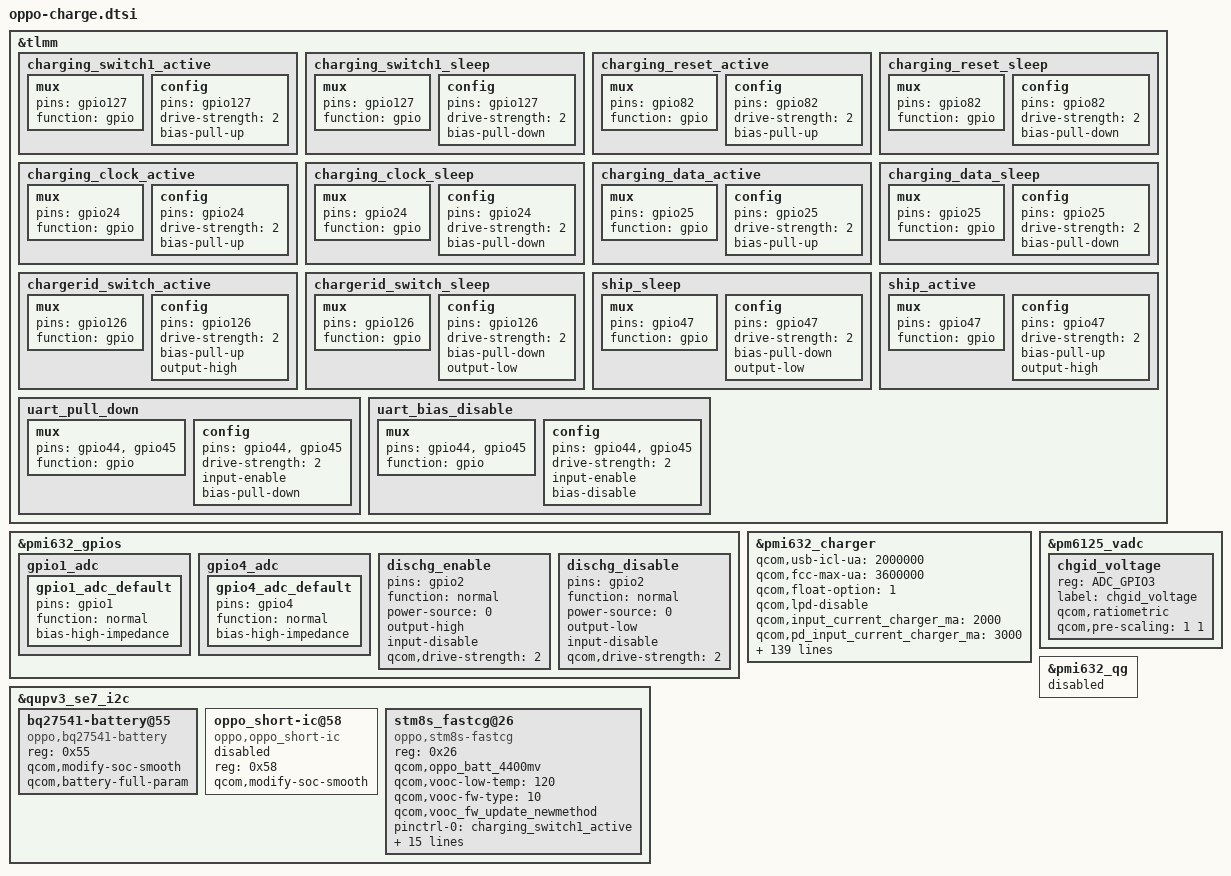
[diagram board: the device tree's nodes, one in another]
/**********************************************************************************
* Copyright (c)  2008-2019  Guangdong OPPO Mobile Comm Corp., Ltd
* VENDOR_EDIT
* Description: OPPO Charge Module Device Tree
*
* Version: 1.0
* Date: 2019-06-10
* Author: Yichun.Chen
*
* ------------------------------ Revision History: --------------------------------
* <version>           <date>                <author>                            <desc>
* Revision 1.0       2019-06-10            Yichun.Chen             Created for new architecture
***********************************************************************************/

&tlmm {
	charging_switch1_active: charging_switch1_active {
		mux {
			pins = "gpio127";
			function = "gpio";
		};

		config {
			pins = "gpio127";
			drive-strength = <2>;
			bias-pull-up;
		};
	};

	charging_switch1_sleep: charging_switch1_sleep {
		mux {
			pins = "gpio127";
			function = "gpio";
		};

		config {
			pins = "gpio127";
			drive-strength = <2>;
			bias-pull-down;
		};
	};
	charging_reset_active: charging_reset_active {
		mux {
			pins = "gpio82";
			function = "gpio";
		};

		config {
			pins = "gpio82";
			drive-strength = <2>;
			bias-pull-up;
		};
	};

	charging_reset_sleep: charging_reset_sleep {
		mux {
			pins = "gpio82";
			function = "gpio";
		};

		config {
			pins = "gpio82";
			drive-strength = <2>;
			bias-pull-down;
		};
	};

	charging_clock_active: charging_clock_active {
		mux {
			pins = "gpio24";
			function = "gpio";
		};

		config {
			pins = "gpio24";
			drive-strength = <2>;
			bias-pull-up;
		};
	};

	charging_clock_sleep: charging_clock_sleep {
		mux {
			pins = "gpio24";
			function = "gpio";
		};

		config {
			pins = "gpio24";
			drive-strength = <2>;
			bias-pull-down;
		};
	};

	charging_data_active: charging_data_active {
		mux {
			pins = "gpio25";
			function = "gpio";
		};

		config {
			pins = "gpio25";
			drive-strength = <2>;
			bias-pull-up;
		};
	};

	charging_data_sleep: charging_data_sleep {
		mux {
			pins = "gpio25";
			function = "gpio";
		};

		config {
			pins = "gpio25";
			drive-strength = <2>;
			bias-pull-down;
		};
	};

	chargerid_switch_active: chargerid_switch_active {
		mux {
			pins = "gpio126";
			function = "gpio";
		};

		config {
			pins = "gpio126";
			drive-strength = <2>;
			bias-pull-up;
			output-high;
		};
	};

	chargerid_switch_sleep: chargerid_switch_sleep {
		mux {
			pins = "gpio126";
			function = "gpio";
		};

		config {
			pins = "gpio126";
			drive-strength = <2>;
			bias-pull-down;
			output-low;
		};
	};

	ship_sleep: ship_sleep {
		mux {
			pins = "gpio47";
			function = "gpio";
		};

		config {
			pins = "gpio47";
			drive-strength = <2>;
			bias-pull-down;
			output-low;
		};
	};

	ship_active: ship_active {
		mux {
			pins = "gpio47";
			function = "gpio";
		};

		config {
			pins = "gpio47";
			drive-strength = <2>;
			bias-pull-up;
			output-high;
		};
	};

	uart_pull_down: uart_pull_down {
		mux {
			pins = "gpio44", "gpio45";
			function = "gpio";
		};

		config {
			pins = "gpio44", "gpio45";
			drive-strength = <2>;
			input-enable;
			bias-pull-down;
		};
	};

	uart_bias_disable: uart_bias_disable {
		mux {
			pins = "gpio44", "gpio45";
			function = "gpio";
		};

		config {
			pins = "gpio44", "gpio45";
			drive-strength = <2>;
			input-enable;
			bias-disable;
		};
	};
};


&pmi632_gpios {
	gpio1_adc {
		gpio1_adc_default: gpio1_adc_default {
			pins = "gpio1"; /* GPIO 1 */
			function = "normal"; /* normal */
			bias-high-impedance; /* DISABLE GPIO1 for ADC*/
		};
	};

	gpio4_adc {
		gpio4_adc_default: gpio4_adc_default {
			pins = "gpio4"; /* GPIO 4 */
			function = "normal"; /* normal */
			bias-high-impedance; /* DISABLE GPIO4 for ADC*/
			};
	};

	dischg_enable: dischg_enable {
		pins = "gpio2";
		function = "normal";
		power-source = <0>;
		output-high;
		input-disable;
		qcom,drive-strength = <2>;
	};

	dischg_disable: dischg_disable {
		pins = "gpio2";
		function = "normal";
		power-source = <0>;
		output-low;
		input-disable;
		qcom,drive-strength = <2>;
	};
};

&pmi632_charger {

	/* qcom options */
	qcom,usb-icl-ua = <2000000>;
	qcom,fcc-max-ua = <3600000>;
	/*qcom,hvdcp-disable;*/
	qcom,float-option = <1>;
	qcom,lpd-disable;

	//for oppo chg framework:
	qcom,input_current_charger_ma = <2000>;
	qcom,pd_input_current_charger_ma = <3000>;
	qcom,input_current_usb_ma = <500>;
	qcom,input_current_led_ma = <2000>;
	qcom,input_current_led_ma_normal = <2000>;
	qcom,input_current_led_ma_warm = <1500>;
	qcom,input_current_led_ma_high = <1000>;
	qcom,input_current_camera_ma = <1200>;
	qcom,input_current_cdp_ma = <2200>;

	qcom,qc_input_current_charger_ma = <2000>;
	qcom,qc_temp_normal_fastchg_current_ma = <3600>;
	qcom,qc_temp_little_cold_fastchg_current_ma_high = <1900>;
	qcom,qc_temp_little_cold_fastchg_current_ma_low = <1100>;
	qcom,qc_temp_cool_fastchg_current_ma_high = <3550>;
	qcom,qc_temp_cool_fastchg_current_ma_low = <2650>;
	qcom,qc_temp_little_cool_fastchg_current_ma = <3600>;
	qcom,qc_temp_warm_fastchg_current_ma = <1150>;




	qcom,iterm_ma = <205>; 			/* 0.05C + 10mA */
	qcom,recharge-mv = <100>;
	qcom,batt_capacity_mah = <4025>;	/* critical capacity */

	qcom,removed_bat_decidegc = <190>;	/* < -19C */

	qcom,cold_bat_decidegc = <20>;		/* -2C ~ 0C */
	qcom,temp_cold_vfloat_mv = <3980>;
	qcom,temp_cold_fastchg_current_ma = <364>;

	qcom,little_cold_bat_decidegc = <0>;	/* 0C ~ 5C */
	qcom,temp_little_cold_vfloat_mv = <4435>;
	qcom,temp_little_cold_fastchg_current_ma = <1100>;
	qcom,temp_little_cold_fastchg_current_ma_high = <1900>;
	qcom,temp_little_cold_fastchg_current_ma_low = <1100>;
	qcom,pd_temp_little_cold_fastchg_current_ma_high = <1850>;
	qcom,pd_temp_little_cold_fastchg_current_ma_low = <1100>;

	qcom,cool_bat_decidegc = <50>;		/* 5C~12C */
	qcom,temp_cool_vfloat_mv = <4435>;
	qcom,temp_cool_fastchg_current_ma_high = <3550>;
	qcom,temp_cool_fastchg_current_ma_low = <2650>;
	qcom,pd_temp_cool_fastchg_current_ma_high = <2550>;
	qcom,pd_temp_cool_fastchg_current_ma_low = <1850>;

	qcom,little_cool_bat_decidegc = <120>;	/* 12C ~ 16C */
	qcom,temp_little_cool_vfloat_mv = <4435>;
	qcom,temp_little_cool_fastchg_current_ma = <3600>;
	qcom,pd_temp_little_cool_fastchg_current_ma = <3600>;

	qcom,normal_bat_decidegc = <160>;	/* 16C ~ 45C */
	qcom,temp_normal_vfloat_mv = <4435>;
	qcom,temp_normal_fastchg_current_ma = <3600>;
	qcom,pd_temp_normal_fastchg_current_ma = <3600>;

	qcom,warm_bat_decidegc = <450>;	/* 45C ~ 53C */
	qcom,temp_warm_vfloat_mv = <4130>;
	qcom,temp_warm_fastchg_current_ma = <1100>;
	qcom,temp_warm_fastchg_current_ma_led_on = <500>;
	qcom,pd_temp_warm_fastchg_current_ma = <1100>;

	qcom,hot_bat_decidegc = <530>;

	qcom,non_standard_vfloat_mv = <3980>;
	qcom,non_standard_fastchg_current_ma = <512>;
	qcom,short_c_bat_cv_mv = <4330>;
	qcom,short_c_bat_vfloat_mv = <3800>;
	qcom,short_c_bat_fastchg_current_ma = <512>;

	qcom,cold_vfloat_sw_limit = <3930>;
	qcom,little_cold_vfloat_sw_limit = <4385>;
	qcom,cool_vfloat_sw_limit = <4385>;
	qcom,little_cool_vfloat_sw_limit = <4385>;
	qcom,normal_vfloat_sw_limit = <4385>;
	qcom,warm_vfloat_sw_limit = <4080>;
	qcom,non_standard_vfloat_sw_limit = <3930>;
	qcom,short_c_bat_vfloat_sw_limit = <3750>;

	qcom,max_chg_time_sec = <36000>;
	qcom,charger_hv_thr = <10000>;
	qcom,charger_recv_thr = <9700>;
	qcom,charger_lv_thr = <3400>;
	qcom,vbatt_full_thr = <4400>;
	qcom,vbatt_hv_thr = <4450>;
	qcom,vfloat_step_mv = <10>;

	qcom,non_standard_vfloat_over_sw_limit = <3990>;
	qcom,cold_vfloat_over_sw_limit = <3990>;
	qcom,little_cold_vfloat_over_sw_limit = <4445>;
	qcom,cool_vfloat_over_sw_limit = <4445>;
	qcom,little_cool_vfloat_over_sw_limit = <4445>;
	qcom,normal_vfloat_over_sw_limit = <4445>;
	qcom,warm_vfloat_over_sw_limit = <4140>;

	qcom,vbatt_power_off = <3300>;
	qcom,vbatt_soc_1 = <3410>;
	//qcom,vooc_project = <1>;
	qcom,vbatt_num = <1>;
//	recharge_after_full;

	qcom,normal_vterm_hw_inc = <18>;
	qcom,non_normal_vterm_hw_inc = <18>;

	//qcom,ffc_support;
	qcom,ffc2_temp_low_decidegc = <120>;
	qcom,ffc2_temp_warm_decidegc = <350>;
	qcom,ffc2_temp_high_decidegc = <400>;
	qcom,ff1_normal_fastchg_ma = <1200>;	/* 12C ~ 35c */
	qcom,ff1_warm_fastchg_ma = <1200>;	/* 35C ~ 40c */
	qcom,ffc2_normal_fastchg_ma = <750>;	/* 12C ~ 35c */
	qcom,ffc2_warm_fastchg_ma = <800>;	/* 35C ~ 40c */
	qcom,ffc_normal_vfloat_sw_limit = <4475>;
	qcom,ffc2_normal_vfloat_sw_limit = <4475>;
	qcom,ff1_exit_step_ma = <600>;
	qcom,ff1_warm_exit_step_ma = <550>;
	qcom,ffc2_exit_step_ma = <150>;
	qcom,ffc2_warm_exit_step_ma = <150>;
	qcom,ffc_temp_normal_vfloat_mv = <4550>;
	qcom,ffc_normal_vfloat_over_sw_limit = <4550>;

	qcom,qc_9v2a_support;
	qcom,qc_temp_cool_decidegc = <220>;
	qcom,qc_temp_normal_decidegc = <340>;
	qcom,qc_temp_warm_decidegc = <370>;
	qcom,qc_temp_little_hot_decidegc = <400>;
	qcom,qc_temp_cool_fastchg_ma = <3600>;	/* 16C ~ 22c */
	qcom,qc_temp_normal_fastchg_ma_hight = <3600>;	/* 22C ~ 34c & <4180mV */
	qcom,qc_temp_normal_fastchg_ma_low = <3600>;	/* 22C ~ 34c & >4180mV */
	qcom,qc_temp_warm_fastchg_ma = <2900>;	/* 34C ~ 37c */
	qcom,qc_temp_little_hot_fastchg_ma = <2700>;	/* 37C ~ 40c */
	qcom,qc_temp_hot_fastchg_ma = <2600>;	/* 40C ~ 45c */

	qcom,default_iterm_ma = <205>;
	qcom,default_temp_normal_fastchg_current_ma = <2000>;
	qcom,default_normal_vfloat_sw_limit = <4385>;
	qcom,default_temp_normal_vfloat_mv = <4435>;
	qcom,default_normal_vfloat_over_sw_limit = <4445>;

	qcom,offset_temp = <0>;
	qcom,check_batt_full_by_sw;
	qcom,external_gauge;
	//qcom,chg_ctrl_by_lcd;
	//qcom,chg_ctrl_by_calling;
	qcom,sw_vfloat_over_protect_enable;

	/* gpio options */
	//qcom,chargerid_switch-gpio = <&tlmm 126 0x00>;
	qcom,ship-gpio = <&tlmm 47 0x00>;
	qcom,dischg-gpio = <&pmi632_gpios 2 0x00>;
	pinctrl-names = "chargerid_switch_active", "chargerid_switch_sleep",
			"ship_active", "ship_sleep",
			"uart_bias_disable", "uart_pull_down",
			"dischg_enable", "dischg_disable",
			"default", "default";
	pinctrl-0 = <&chargerid_switch_active>;
	pinctrl-1 = <&chargerid_switch_sleep>;
	pinctrl-2 = <&ship_active>;
	pinctrl-3 = <&ship_sleep>;
	pinctrl-4 = <&uart_bias_disable>;
	pinctrl-5 = <&uart_pull_down>;
	pinctrl-6 = <&dischg_enable>;
	pinctrl-7 = <&dischg_disable>;
	pinctrl-8 = <&gpio1_adc_default>;
	pinctrl-9 = <&gpio4_adc_default>;
};

&qupv3_se7_i2c {
	status = "ok";

	bq27541-battery@55 {
		status = "ok";
		compatible = "oppo,bq27541-battery";
		reg = <0x55>;
		qcom,modify-soc-smooth;
		qcom,battery-full-param;
	};


	oppo_short-ic@58 {
		status = "disabled";
		compatible = "oppo,oppo_short-ic";
		reg = <0x58>;
		qcom,modify-soc-smooth;
	};


	stm8s_fastcg@26 {
		status = "ok";
		compatible = "oppo,stm8s-fastcg";
		reg = <0x26>;
		qcom,oppo_batt_4400mv;
		qcom,vooc-low-temp = <120>;
		qcom,vooc-fw-type = <10>;
		qcom,vooc_fw_update_newmethod;

		pinctrl-names = "switch1_act_switch2_act", "switch1_sleep_switch2_sleep",
				"switch1_act_switch3_act", "switch1_sleep_switch3_sleep",
				"switch1_act_switch2_sleep", "switch1_sleep_switch2_act",
				"clock_active","clock_sleep",
				"data_active","data_sleep",
				"reset_active","reset_sleep";
		pinctrl-0 = <&charging_switch1_active>;
		pinctrl-1 = <&charging_switch1_sleep >;
		pinctrl-2 = <&charging_switch1_active>;
		pinctrl-3 = <&charging_switch1_sleep >;
		pinctrl-4 = <&charging_switch1_active>;
		pinctrl-5 = <&charging_switch1_sleep>;
		pinctrl-6 = <&charging_clock_active >;
		pinctrl-7 = <&charging_clock_sleep >;
		pinctrl-8 = <&charging_data_active >;
		pinctrl-9 = <&charging_data_sleep >;
		pinctrl-10 = <&charging_reset_active >;
		pinctrl-11 = <&charging_reset_sleep >;

		qcom,charging_switch1-gpio = <&tlmm 127 0x00>;
		qcom,charging_reset-gpio = <&tlmm 82 0x00>;
		qcom,charging_clock-gpio = <&tlmm 24 0x00>;
		qcom,charging_data-gpio = <&tlmm 25 0x00>;
	};
};

&pm6125_vadc {
	chgid_voltage {
		reg = <ADC_GPIO3>;
		label = "chgid_voltage";
		qcom,ratiometric;
		qcom,pre-scaling = <1 1>;
	};
};

&pmi632_qg {
	status="disabled";
};
